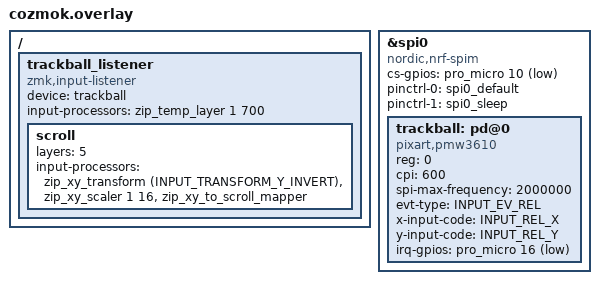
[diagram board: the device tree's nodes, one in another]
#include <dt-bindings/zmk/bt.h>
#include <input/processors.dtsi>
#include <dt-bindings/zmk/input_transform.h>
#include "cozmok_pinctrl.dtsi"
#include "cozmok.dtsi"

&spi0 {
    status = "okay";
    cs-gpios =  <&pro_micro 10 GPIO_ACTIVE_LOW>;
    pinctrl-0 = <&spi0_default>;
    pinctrl-1 = <&spi0_sleep>;
    pinctrl-names = "default", "sleep";
    compatible = "nordic,nrf-spim";

    trackball: pd@0 {
        status = "okay";
        compatible = "pixart,pmw3610";
        reg = <0>;
	    cpi = <600>;
        spi-max-frequency = <2000000>;
        evt-type = <INPUT_EV_REL>;
        x-input-code = <INPUT_REL_X>;
        y-input-code = <INPUT_REL_Y>;
        irq-gpios = <&pro_micro 16 (GPIO_ACTIVE_LOW | GPIO_PULL_UP)>;
    };
};

/ {
  trackball_listener {
    status = "okay";
    compatible = "zmk,input-listener";
    device = <&trackball>;
    input-processors = <&zip_temp_layer 1 700>;
    scroll {
        layers = <5>;
        input-processors = <&zip_xy_transform (INPUT_TRANSFORM_Y_INVERT)>, <&zip_xy_scaler 1 16>, <&zip_xy_to_scroll_mapper>;
    };
  };
};
